VERSION ""

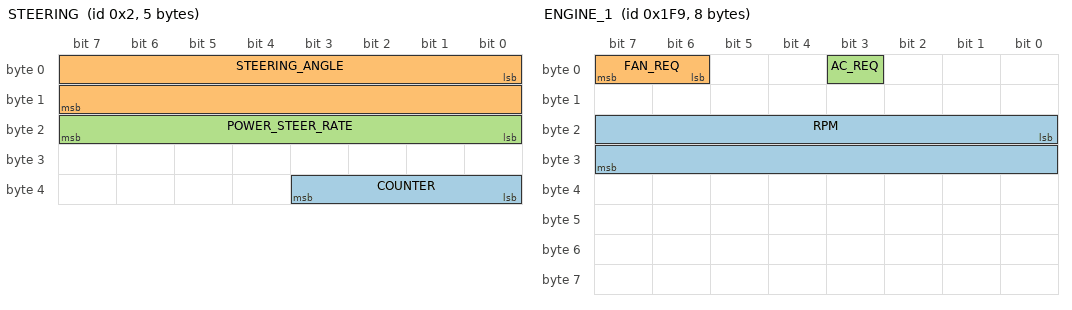
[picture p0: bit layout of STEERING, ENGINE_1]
BO_ 2 STEERING: 5 XXX
 SG_ COUNTER : 35|4@0+ (1,0) [0|255] "" XXX
 SG_ STEERING_ANGLE : 0|16@1- (0.1,0) [0|65535] "deg" XXX
 SG_ POWER_STEER_RATE : 23|8@0+ (1,0) [0|255] "" XXX

BO_ 505 ENGINE_1: 8 XXX
 SG_ RPM : 16|16@1+ (0.125,0) [0|45000] "R/min" XXX
 SG_ FAN_REQ : 6|2@1+ (1,0) [0|3] "" XXX
 SG_ AC_REQ : 3|1@1+ (1,0) [0|1] "" XXX

BO_ 561 ENGINE_2: 8 XXX
 SG_ Pedal_position : 16|8@1+ (0.5,0) [0|200] "%" XXX

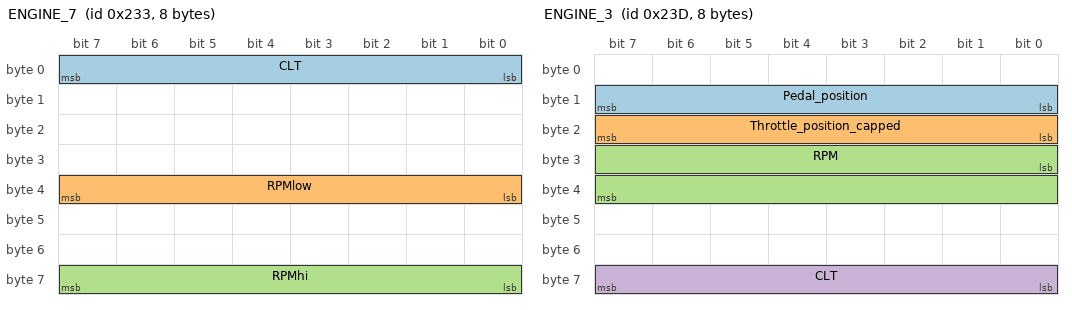
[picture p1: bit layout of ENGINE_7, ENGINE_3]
BO_ 563 ENGINE_7: 8 XXX
 SG_ CLT : 0|8@1+ (0.366666,0) [0|255] "C" XXX
 SG_ RPMlow : 32|8@1+ (3.15,0) [0|45000] "R/min" XXX
 SG_ RPMhi : 56|8@1+ (3.15,0) [0|45000] "R/min" XXX

BO_ 573 ENGINE_3: 8 XXX
 SG_ Pedal_position : 8|8@1+ (0.392,0) [0|255] "%" XXX
 SG_ Throttle_position_capped : 16|8@1+ (0.392,0) [0|255] "%" XXX
 SG_ RPM : 24|16@1+ (3.15,0) [0|45000] "R/min" XXX
 SG_ CLT : 56|8@1+ (0.366666,0) [0|255] "C" XXX

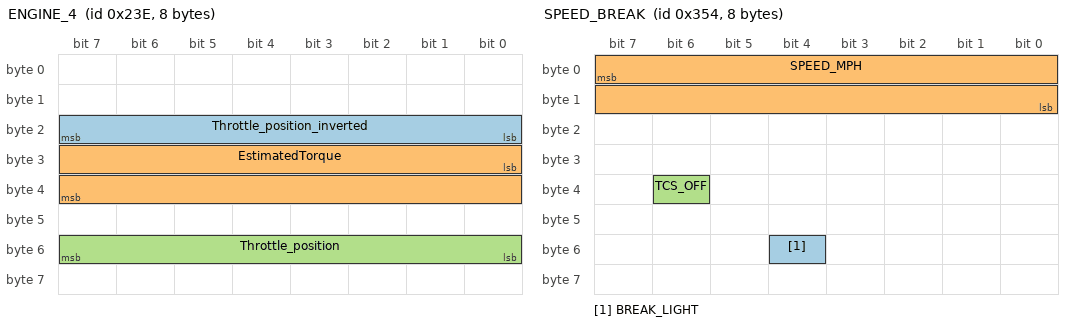
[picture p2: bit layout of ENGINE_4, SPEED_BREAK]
BO_ 574 ENGINE_4: 8 XXX
 SG_ Throttle_position_inverted : 16|8@1+ (0.392,0) [0|255] "%" XXX
 SG_ EstimatedTorque : 24|16@1+ (0.1,0) [0|45000] "nM" XXX
 SG_ Throttle_position : 48|8@1+ (0.392,0) [0|255] "%" XXX

BO_ 595 TCU_1: 8 XXX
 SG_ SHAFT_1_SPEED : 32|16@1+ (1,0) [0|45000] "r/min" XXX
 SG_ SHAFT_2_SPEED : 48|16@1+ (1,0) [0|45000] "r/min" XXX

BO_ 640 SPEED: 8 XXX
 SG_ SPEED : 32|16@1+ (0.01,0) [0|45000] "km/h" XXX

BO_ 644 ABS_1: 8 XXX
 SG_ WHEEL_1 : 0|16@1+ (0.01,0) [0|45000] "km/h" XXX
 SG_ WHEEL_2 : 15|16@1+ (0.01,0) [0|45000] "km/h" XXX

BO_ 645 ABS_2: 8 XXX
 SG_ WHEEL_3 : 0|16@1+ (0.01,0) [0|45000] "km/h" XXX
 SG_ WHEEL_4 : 15|16@1+ (0.01,0) [0|45000] "km/h" XXX

BO_ 852 SPEED_BREAK: 8 XXX
 SG_ BREAK_LIGHT : 52|1@0+ (1,0) [0|3] "" XXX
 SG_ SPEED_MPH : 7|16@0+ (0.0066,0) [0|65535] "mph" XXX
 SG_ TCS_OFF : 38|1@0+ (1,0) [0|255] "" XXX

BO_ 861 BCM: 8 XXX

BO_ 1361 ENGINE_5: 8 XXX
 SG_ CLT : 0|8@1+ (1,-45) [-45|150] "" XXX

BO_ 1408 ENGINE_6: 8 XXX
 SG_ RPM : 7|16@0+ (1.5,0) [0|65535] "" XXX
 SG_ OIL_TEMP : 32|8@1+ (1,-40) [-40|150] "" XXX

BU_: XXX

CM_ "AUTOGENERATED FILE, DO NOT EDIT";

CM_ "Imported file _comma.dbc starts here";
CM_ "BO_ STEERING_IPAS_COMMA: Copy of msg 614 so we can do angle control while the Park Assist ECU is connected (Panda spoofs 614 with 359 on connector J70). Note that addresses 0x266 and 0x167 are checksum-invariant";

CM_ "BO_ SECONDARY_STEER_ANGLE: ZSS is a high-precision steering angle sensor that can replace the lower resolution sensor in most TSS1 Toyotas. Learn more: https://github.com/commaai/openpilot/wiki/Toyota-Lexus#zorro-steering-sensor-zss";

CM_ "BO_ SDSU: The sDSU is a modified DSU for use in TSS1 Toyotas. Learn more: https://github.com/wocsor/panda/tree/smart_dsu";
CM_ SG_ 767 FD_BUTTON "The follow distance button signal as forwarded by the sdsu";

CM_ "Imported file _toyota_2017.dbc starts here";
CM_ SG_ 36 YAW_RATE "verify";
CM_ SG_ 36 ACCEL_X "x-axis accel";
CM_ SG_ 37 STEER_FRACTION "1/15th of the signal STEER_ANGLE, which is 1.5 deg; note that 0x8 is never set";
CM_ SG_ 37 STEER_RATE "factor is tbd";
CM_ SG_ 466 NEUTRAL_FORCE "force in newtons the engine/electric motors are applying without any acceleration commands or user input";
CM_ SG_ 466 ACC_BRAKING "whether brakes are being actuated from ACC command";
CM_ SG_ 466 ACCEL_NET "net acceleration produced by the system, given ACCEL_CMD, road grade and other factors";
CM_ SG_ 466 CRUISE_STATE "Active state is 8, if standstill is requested will switch to state 11(3 sec timer), after timer is elapsed will switch into state 7(standstill). If plus button was pressed - status 9, minus button pressed - status 10";
CM_ SG_ 467 ACC_FAULTED "1 when ACC is faulted and the PCM disallows engagement";
CM_ SG_ 467 SET_SPEED "43 km/h are shown as 28 mph, so conversion isn't perfect";
CM_ SG_ 467 LOW_SPEED_LOCKOUT "in low speed lockout, system would always disengage below 28mph";
CM_ SG_ 560 BRAKE_PRESSED "another brake pressed?";
CM_ SG_ 581 GAS_PEDAL "it seems slightly filtered";
CM_ SG_ 608 STEER_TORQUE_DRIVER "driver torque";
CM_ SG_ 608 STEER_OVERRIDE "set when driver torque exceeds a certain value";
CM_ SG_ 614 ANGLE "set to measured angle when ipas control isn't active";
CM_ SG_ 643 _COUNTER "only used on cars that use this msg for cruise control";
CM_ SG_ 643 BRAKE_STATUS "only used on cars that use this msg for cruise control";
CM_ SG_ 643 PRECOLLISION_ACTIVE "set 0.5s before any braking";
CM_ SG_ 835 ACC_TYPE "if 2, car is likely to have a permanent low speed lockout. 1 is ok";
CM_ SG_ 835 RADAR_DIRTY "Display Clean Radar Sensor message on HUD";
CM_ SG_ 835 ACC_MALFUNCTION "display ACC fault on dash if set to 1";
CM_ SG_ 835 ACC_CUT_IN "Display blinking yellow lead if set to 1";
CM_ SG_ 835 DISTANCE "Cycle through ACC following distance from long, mid, short when set to 1";
CM_ SG_ 835 ITS_CONNECT_LEAD "Displayed when lead car is capable of ITS Connect";
CM_ SG_ 835 ALLOW_LONG_PRESS "Enable Toyota's factory set speed increment behaviour, available on both metrics cars and imperial unit cars";
CM_ SG_ 835 PERMIT_BRAKING "Original ACC has this going high when a car in front is detected. In openpilot and before the PERMIT_BRAKING name, this was 'SET_ME_1' and is hardcoded to be high. Unsure if only informational or has an effect though existing usage in openpilot is to always set it to 1. Originally 'PMTBRKG' in the leaked toyota_2017_ref_pt.dbc file and name expansion speculated to be PerMiT BRaKinG.";
CM_ SG_ 835 ACCEL_CMD_ALT "Copy of main ACCEL_CMD, but across 8 bits instead of 16 bits like ACCEL_CMD. Unsure if only informational or has an effect. Likely informational as existing openpilot sets this to 0 and no loss of functionality observed. Originally 'AT_RAW' in leaked toyota_2017_ref_pt.dbc file.";
CM_ SG_ 865 GAS_PEDAL_ALT "copy of main GAS_PEDAL. Both use 8 bits. Might indicate that this message is for pedals.";
CM_ SG_ 865 CLUTCH_RELEASED "boolean of clutch for 6MT.";
CM_ SG_ 865 ACC_FAULTED "1 when ACC is faulted and the PCM disallows engagement. Also describes a lockout when the ACC_CONTROL->ACC_MALFUNCTION bit is set.";
CM_ SG_ 921 UI_SET_SPEED "set speed shown in the vehicle's UI with the vehicle's unit";
CM_ SG_ 921 TEMP_ACC_FAULTED "1 when the UI is displaying or playing fault-related alerts or sounds. Also 1 when pressing main on.";
CM_ SG_ 951 BRAKE_LIGHTS_ACC "brake lights when ACC commands decel";
CM_ SG_ 956 GEAR "on 6MT, only R shows.";
CM_ SG_ 1009 UI_SET_SPEED "units seem to be whatever the car is set to";
CM_ SG_ 1041 PCS_INDICATOR "Pre-Collision System Indicator";
CM_ SG_ 1041 PCS_SENSITIVITY "Pre-Collision System Sensitivity";
CM_ SG_ 1041 PCS_DUST "alert: Front Camera Low Visibility Unavailable See Owner's Manual";
CM_ SG_ 1041 PCS_DUST2 "alert: Pre-Collision System Radar Sensor Blocked Unavailable Clean Radar Sensor";
CM_ SG_ 1041 PCS_TEMP "alert: Front Camera Out of Temperature Range Unavailable Wait until Normal Temperature";
CM_ SG_ 1041 PCS_TEMP2 "alert: Pre-Collision System Out of Temperature Range Unavailable See Owner's Manual";
CM_ SG_ 1041 FRD_ADJ "alert: ERROR ADJUSTING FRONT RADAR BEAM";
CM_ SG_ 1042 LDA_SA_TOGGLE "LDA Steering Assist Toggle";
CM_ SG_ 1042 LDW_EXIST "Unclear what this is, it's usually set to 0";
CM_ SG_ 1042 LDA_SENSITIVITY "LDA Sensitivity";
CM_ SG_ 1042 LDA_ON_MESSAGE "Display LDA Turned ON message";
CM_ SG_ 1042 REPEATED_BEEPS "LDA audible warning";
CM_ SG_ 1042 LDA_UNAVAILABLE_QUIET "LDA toggles and sensitivity settings are greyed out if set to 1";
CM_ SG_ 1042 LDA_MESSAGES "Various LDA Messages";
CM_ SG_ 1042 LDA_FRONT_CAMERA_BLOCKED "originally LDAFCVB, LDA related settings are greyed out if set to 1";
CM_ SG_ 1042 TAKE_CONTROL "Please Control Steering Wheel warning";
CM_ SG_ 1042 LANE_SWAY_TOGGLE "Lane Sway Warning System SWS Switch";
CM_ SG_ 1042 LANE_SWAY_WARNING "Lane Sway Warning System Triggered";
CM_ SG_ 1042 LANE_SWAY_FLD "Unknown signal for Lane Sway Warning System, set to 7 on stock system when SWS is enabled, 0 when SWS is disabled";
CM_ SG_ 1042 LANE_SWAY_BUZZER "Similar to TWO_BEEPS";
CM_ SG_ 1042 SET_ME_X01 "empty bit on leaked dbc, always set to 1 during normal operations";
CM_ SG_ 1042 SET_ME_X02 "empty bit on leaked dbc, always set to 2 during normal operations";
CM_ SG_ 1083 STATE "when the dashboard button is pressed, the value changes from zero to non-zero";
CM_ SG_ 1161 SPDVAL1 "Numbers 0-199 is displayed, 200-254 displays circle without number and 255 is for no limit.";
CM_ SG_ 1161 SYNCID1 "counter from 1 to f at 1 Hz";
CM_ SG_ 1161 SPDVAL2 "conditional speed value 70";
CM_ SG_ 1162 SGNNUMP "1 if SPDVAL1 is set, otherwise 0";
CM_ SG_ 1162 SYNCID2 "counter from 1 to f at 1 Hz";
CM_ SG_ 1163 TSREQPD "always 1";
CM_ SG_ 1163 TSRMSW "always 1";
CM_ SG_ 1163 OTSGNNTM "always 3";
CM_ SG_ 1163 NTLVLSPD "always 3";
CM_ SG_ 1163 OVSPNTM "always 3";
CM_ SG_ 1163 OVSPVALL "-5 at start then 2 after 2 seconds";
CM_ SG_ 1163 OVSPVALM "-5 at start then 5 after 2 seconds";
CM_ SG_ 1163 OVSPVALH "-5 at start then 10 after 2 seconds";
CM_ SG_ 1163 TSRSPU "always 1";
CM_ SG_ 1552 UI_SPEED "Does not appear to match dash";
CM_ SG_ 1552 METER_SLIDER_BRIGHTNESS_PCT "Combination display brightness setting, scales from 12 per cent to 100 per cent, reflects combination meter settings only, not linked with headlight state";
CM_ SG_ 1552 METER_SLIDER_LOW_BRIGHTNESS "Combination display low brightness mode, also controls footwell lighting";
CM_ SG_ 1552 METER_SLIDER_DIMMED "Combination display slider not at max, reflects combination meter settings only, not linked with headlight state";
CM_ SG_ 1553 ODOMETER "Unit is dependent upon units signal";
CM_ SG_ 1592 LOCK_STATUS_CHANGED "1 on rising edge of lock/unlocking";
CM_ SG_ 1592 LOCK_STATUS "The next 3 bits always seem to follow this signal.";
CM_ SG_ 1592 LOCKED_VIA_KEYFOB "1 for as long as car is locked with key fob or door handle touch";

CM_ "toyota_nodsu_pt.dbc starts here";

CM_ SG_ 401 PERCENTAGE "driver override percentage (0-100), very close to steeringPressed in OP";
CM_ SG_ 401 TORQUE_WIND_DOWN "used to wind down torque on user override";
CM_ SG_ 401 ANGLE "angle of car relative to lane center on LTA camera";
CM_ SG_ 401 STEER_ANGLE_CMD "desired angle, OEM steers up to 95 degrees, no angle limit but torque will bottom out";
CM_ SG_ 401 CLEAR_HOLD_STEERING_ALERT "set to 1 when user clears LKAS_HUD->LDA_ALERT ('Hold Steering') by applying torque to steering wheel";
CM_ SG_ 401 STEER_REQUEST "enable bit for steering, 1 to steer, 0 to not";
CM_ SG_ 401 STEER_REQUEST_2 "enable bit for steering, 1 to steer, 0 to not";
CM_ SG_ 401 LKA_ACTIVE "1 when using LTA for LKA";
CM_ SG_ 401 SETME_X1 "usually 1, seen at 0 on some South American Corollas indicating lack of stock Lane Tracing Assist";
CM_ SG_ 401 SETME_X3 "almost completely correlates with Toyota Safety Sense version, but may instead describe max torque when using LTA. if TSS 2.5 or 2022 RAV4, this is always 1. if TSS 2.0 this is always 3 (or 0 on Alphard, Highlander, NX)";
CM_ SG_ 550 BRAKE_PRESSURE "seems prop to pedal force";
CM_ SG_ 550 BRAKE_POSITION "seems proportional to pedal displacement, unclear the max value of 0x1c8";
CM_ SG_ 610 TYPE "seems 1 on Corolla, 0 on all others";
CM_ SG_ 881 GAS_PEDAL "not set on all cars, only seen on TSS 2.5 Camry Hybrid so far";
CM_ SG_ 881 STEER_ANGLE "matches STEER_TORQUE_SENSOR->STEER_ANGLE";
CM_ SG_ 881 TURN_SIGNALS "flipped on some cars";
CM_ SG_ 881 LDA_SA_TOGGLE "not applicable for all cars";
CM_ SG_ 881 LTA_STEER_REQUEST "only applicable for TSS 2.5: matches STEERING_LTA->STEER_REQUEST";
CM_ SG_ 881 UNKNOWN "related to steering wheel angle";
CM_ SG_ 881 STEERING_PRESSED "only applicable for TSS 2.5: low sensitivity steering wheel pressed by driver signal";
CM_ SG_ 1014 L_ADJACENT "vehicle adjacent left side of car. enabled above 10mph, regardless of ADJACENT_ENABLED or APPROACHING_ENABLED";
CM_ SG_ 1014 L_APPROACHING "vehicle approaching from left side of car. enabled above 10mph, regardless of ADJACENT_ENABLED or APPROACHING_ENABLED";
CM_ SG_ 1014 R_ADJACENT "vehicle adjacent right side of car. enabled above 10mph, regardless of ADJACENT_ENABLED or APPROACHING_ENABLED";
CM_ SG_ 1014 R_APPROACHING "vehicle approaching from right side of car. enabled above 10mph, regardless of ADJACENT_ENABLED or APPROACHING_ENABLED";
CM_ SG_ 1014 ADJACENT_ENABLED "when BSM is enabled in settings, this is on along with APPROACHING_ENABLED. this controls bsm alert visibility";
CM_ SG_ 1014 APPROACHING_ENABLED "when BSM is enabled in settings, this is on along with ADJACENT_ENABLED. this controls bsm alert visibility";

VAL_ 780 CRUISE_SPEED 255 "no_speed" 252 "stopped";
VAL_ 780 HUD_LEAD 3 "acc_off" 2 "solid_car" 1 "dashed_car" 0 "no_car";
VAL_ 884 DASHBOARD_ALERT 0 "none" 51 "acc_problem" 55 "cmbs_problem" 75 "key_not_detected" 79 "fasten_seatbelt" 111 "lkas_problem" 131 "brake_system_problem" 132 "brake_hold_problem" 139 "tbd" 161 "door_open";
VAL_ 891 WIPERS 4 "High" 2 "Low" 0 "Off";

VAL_ 399 STEER_STATUS 6 "tmp_fault" 5 "fault_1" 4 "no_torque_alert_2" 3 "low_speed_lockout" 2 "no_torque_alert_1" 0 "normal";

VAL_ 829 BEEP 3 "single_beep" 2 "triple_beep" 1 "repeated_beep" 0 "no_beep";

VAL_ 401 GEAR_SHIFTER 32 "L" 16 "S" 8 "D" 4 "N" 2 "R" 1 "P";
VAL_ 401 GEAR 7 "L" 10 "S" 4 "D" 3 "N" 2 "R" 1 "P";
VAL_ 419 GEAR_SHIFTER 2 "S" 32 "D" 16 "N" 8 "R" 4 "P";
VAL_ 419 GEAR 26 "S" 20 "D" 19 "N" 18 "R" 17 "P";
VAL_ 545 ECON_ON_2 0 "off" 3 "on";
VAL_ 662 CRUISE_BUTTONS 7 "tbd" 6 "tbd" 5 "tbd" 4 "accel_res" 3 "decel_set" 2 "cancel" 1 "main" 0 "none";
VAL_ 662 CRUISE_SETTING 3 "distance_adj" 2 "tbd" 1 "lkas_button" 0 "none";
